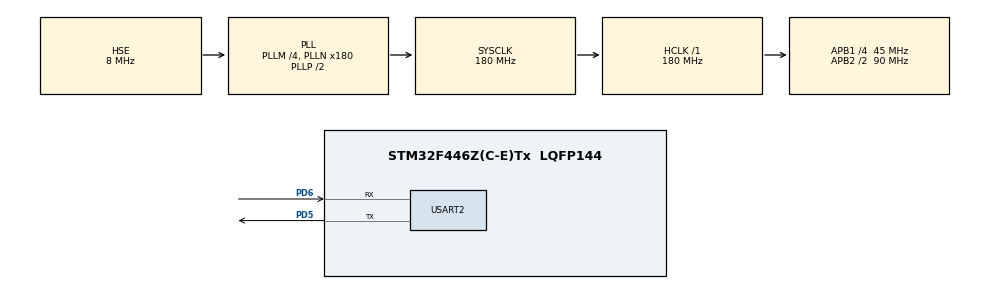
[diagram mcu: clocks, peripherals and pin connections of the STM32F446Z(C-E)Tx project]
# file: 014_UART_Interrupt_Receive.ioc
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Mcu.Family=STM32F4
Mcu.Name=STM32F446Z(C-E)Tx
Mcu.Package=LQFP144
NVIC.PriorityGroup=NVIC_PRIORITYGROUP_4
NVIC.USART2_IRQn=true\:0\:0\:false\:false\:true\:true\:true\:true
PA13.Mode=Serial_Wire
PA13.Signal=SYS_JTMS-SWDIO
PA14.Mode=Serial_Wire
PA14.Signal=SYS_JTCK-SWCLK
PC14-OSC32_IN.Mode=LSE-External-Oscillator
PC14-OSC32_IN.Signal=RCC_OSC32_IN
PC15-OSC32_OUT.Mode=LSE-External-Oscillator
PC15-OSC32_OUT.Signal=RCC_OSC32_OUT
PD5.Mode=Asynchronous
PD5.Signal=USART2_TX
PD6.Mode=Asynchronous
PD6.Signal=USART2_RX
PH0-OSC_IN.Mode=HSE-External-Oscillator
PH0-OSC_IN.Signal=RCC_OSC_IN
PH1-OSC_OUT.Mode=HSE-External-Oscillator
PH1-OSC_OUT.Signal=RCC_OSC_OUT
ProjectManager.HeapSize=0x200
ProjectManager.StackSize=0x400
ProjectManager.TargetToolchain=STM32CubeIDE
RCC.48MHZClocksFreq_Value=24000000
RCC.AHBFreq_Value=180000000
RCC.APB1CLKDivider=RCC_HCLK_DIV4
RCC.APB1Freq_Value=45000000
RCC.APB1TimFreq_Value=90000000
RCC.APB2CLKDivider=RCC_HCLK_DIV2
RCC.APB2Freq_Value=90000000
RCC.APB2TimFreq_Value=180000000
RCC.CortexFreq_Value=180000000
RCC.HCLKFreq_Value=180000000
RCC.HSE_VALUE=8000000
RCC.HSI_VALUE=16000000
RCC.PLLM=4
RCC.PLLMUL=RCC_PLL_MUL9
RCC.PLLN=180
RCC.PLLQ=7
RCC.PLLSourceVirtual=RCC_PLLSOURCE_HSE
RCC.PRESCALERUSB=RCC_USBCLKSOURCE_PLL_DIV1_5
RCC.SYSCLKFreq_VALUE=180000000
RCC.SYSCLKSource=RCC_SYSCLKSOURCE_PLLCLK
RCC.SYSCLKSourceVirtual=RCC_SYSCLKSOURCE_PLLCLK
RCC.USBFreq_Value=51428571.428571425
RCC.VCOOutputFreq_Value=360000000
USART2.VirtualMode=VM_ASYNC
board=NUCLEO-F446ZE

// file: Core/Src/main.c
/* USER CODE BEGIN Header */
/**
  ******************************************************************************
  * @file           : main.c
  * @brief          : Main program body
  ******************************************************************************
  * @attention
  *
  * Copyright (c) 2026 STMicroelectronics.
  * All rights reserved.
  *
  * This software is licensed under terms that can be found in the LICENSE file
  * in the root directory of this software component.
  * If no LICENSE file comes with this software, it is provided AS-IS.
  *
  ******************************************************************************
  */
/* USER CODE END Header */
#include "main.h"

/* USER CODE BEGIN PD */
uint8_t rxByte;

int8_t data[20];

uint8_t receiving = 0;

uint8_t index = 0;

uint8_t length = 0;
/* USER CODE END PD */

UART_HandleTypeDef huart2;

void SystemClock_Config(void);
static void MX_GPIO_Init(void);
static void MX_USART2_UART_Init(void);

int main(void)
{

  /* MCU Configuration--------------------------------------------------------*/

  /* Reset of all peripherals, Initializes the Flash interface and the Systick. */
  HAL_Init();

  /* Configure the system clock */
  SystemClock_Config();

  /* Initialize all configured peripherals */
  MX_GPIO_Init();
  MX_USART2_UART_Init();
  /* USER CODE BEGIN 2 */
  HAL_UART_Receive_IT(&huart2, &rxByte, 1);

  /* USER CODE END 2 */

  /* Infinite loop */
  while (1)
  {

  }
}

void SystemClock_Config(void)
{
  RCC_OscInitTypeDef RCC_OscInitStruct = {0};
  RCC_ClkInitTypeDef RCC_ClkInitStruct = {0};

  /** Configure the main internal regulator output voltage
  */
  __HAL_RCC_PWR_CLK_ENABLE();
  __HAL_PWR_VOLTAGESCALING_CONFIG(PWR_REGULATOR_VOLTAGE_SCALE1);

  /** Initializes the RCC Oscillators according to the specified parameters
  * in the RCC_OscInitTypeDef structure.
  */
  RCC_OscInitStruct.OscillatorType = RCC_OSCILLATORTYPE_HSE;
  RCC_OscInitStruct.HSEState = RCC_HSE_ON;
  RCC_OscInitStruct.PLL.PLLState = RCC_PLL_ON;
  RCC_OscInitStruct.PLL.PLLSource = RCC_PLLSOURCE_HSE;
  RCC_OscInitStruct.PLL.PLLM = 4;
  RCC_OscInitStruct.PLL.PLLN = 180;
  RCC_OscInitStruct.PLL.PLLP = RCC_PLLP_DIV2;
  RCC_OscInitStruct.PLL.PLLQ = 7;
  RCC_OscInitStruct.PLL.PLLR = 2;
  if (HAL_RCC_OscConfig(&RCC_OscInitStruct) != HAL_OK)
  {
    Error_Handler();
  }

  /** Activate the Over-Drive mode
  */
  if (HAL_PWREx_EnableOverDrive() != HAL_OK)
  {
    Error_Handler();
  }

  /** Initializes the CPU, AHB and APB buses clocks
  */
  RCC_ClkInitStruct.ClockType = RCC_CLOCKTYPE_HCLK|RCC_CLOCKTYPE_SYSCLK
                              |RCC_CLOCKTYPE_PCLK1|RCC_CLOCKTYPE_PCLK2;
  RCC_ClkInitStruct.SYSCLKSource = RCC_SYSCLKSOURCE_PLLCLK;
  RCC_ClkInitStruct.AHBCLKDivider = RCC_SYSCLK_DIV1;
  RCC_ClkInitStruct.APB1CLKDivider = RCC_HCLK_DIV4;
  RCC_ClkInitStruct.APB2CLKDivider = RCC_HCLK_DIV2;

  if (HAL_RCC_ClockConfig(&RCC_ClkInitStruct, FLASH_LATENCY_5) != HAL_OK)
  {
    Error_Handler();
  }
}

static void MX_USART2_UART_Init(void)
{

  huart2.Instance = USART2;
  huart2.Init.BaudRate = 115200;
  huart2.Init.WordLength = UART_WORDLENGTH_8B;
  huart2.Init.StopBits = UART_STOPBITS_1;
  huart2.Init.Parity = UART_PARITY_NONE;
  huart2.Init.Mode = UART_MODE_TX_RX;
  huart2.Init.HwFlowCtl = UART_HWCONTROL_NONE;
  huart2.Init.OverSampling = UART_OVERSAMPLING_16;
  if (HAL_UART_Init(&huart2) != HAL_OK)
  {
    Error_Handler();
  }

}

static void MX_GPIO_Init(void)
{

  /* GPIO Ports Clock Enable */
  __HAL_RCC_GPIOC_CLK_ENABLE();
  __HAL_RCC_GPIOH_CLK_ENABLE();
  __HAL_RCC_GPIOA_CLK_ENABLE();
  __HAL_RCC_GPIOD_CLK_ENABLE();

}

/* USER CODE BEGIN 4 */
void HAL_UART_RxCpltCallback(UART_HandleTypeDef *huart)

{

    if(huart->Instance == USART2)

    {

        // START BYTE DETECTED

        if(rxByte == 0xAA)

        {

            receiving = 1;

            index = 0;

        }

        else if(receiving)

        {

            data[index++] = rxByte;

            // FIXED LENGTH = 5 BYTES

            if(index >= 6)

            {

                receiving = 0;

                // FULL PACKET RECEIVED

                // data[0..4]

                // Example debug

            }

        }

        HAL_UART_Receive_IT(&huart2, &rxByte, 1);

    }

}
/* USER CODE END 4 */

void Error_Handler(void)
{
  __disable_irq();
  while (1)
  {
  }
}
